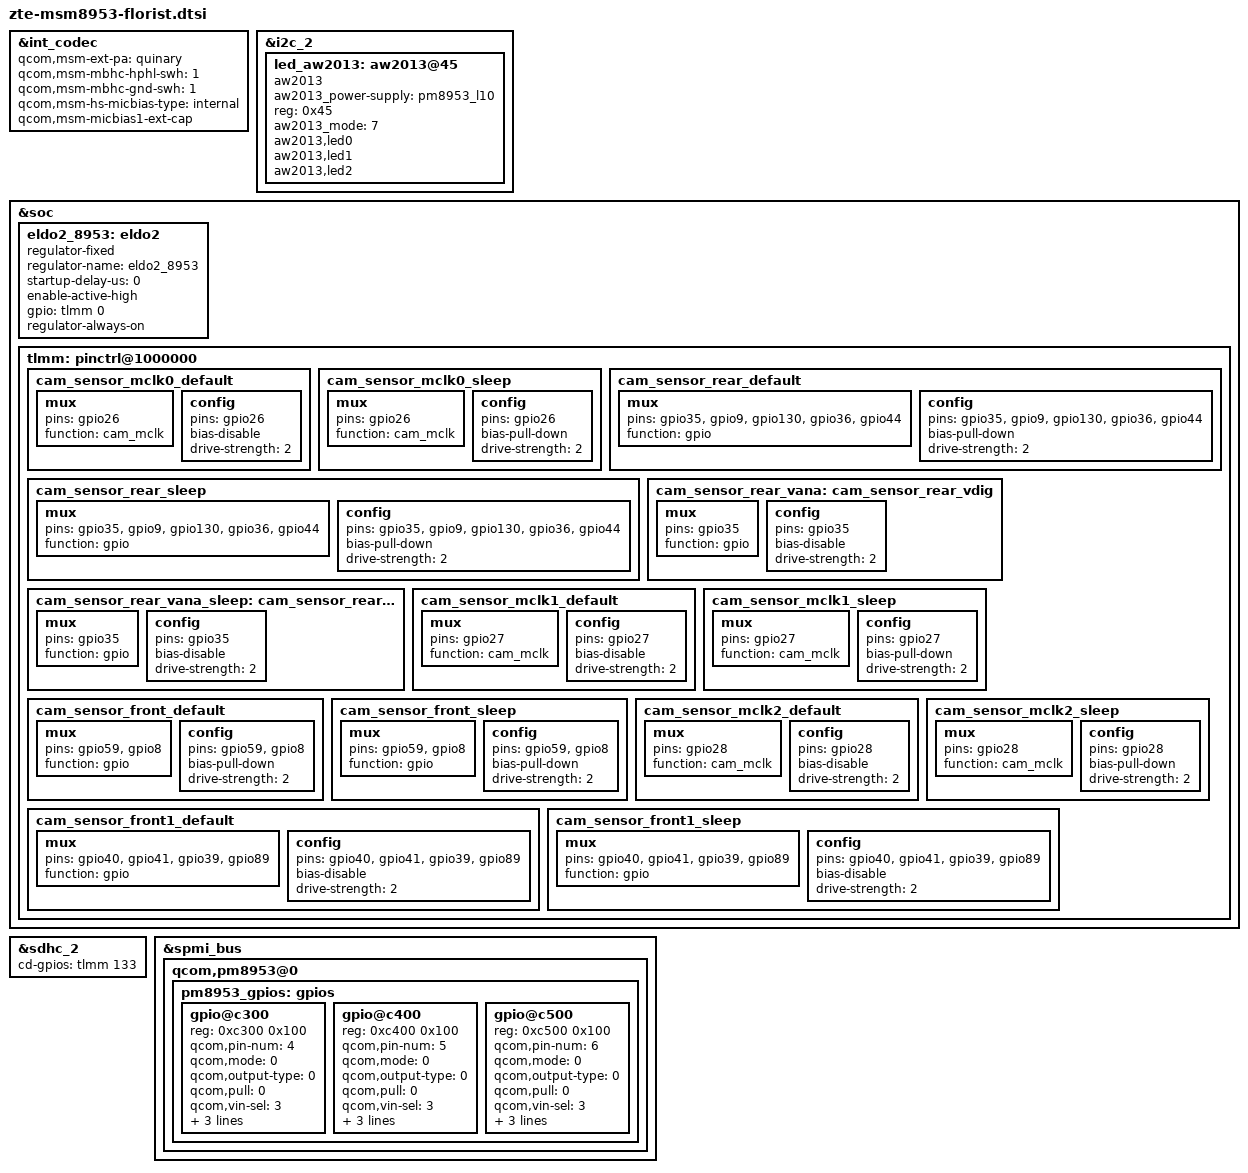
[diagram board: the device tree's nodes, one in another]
/*
 * device tree for zte florist board
 */

#include "touch-key-backlight-florist.dtsi"

&int_codec {
	qcom,msm-ext-pa = "quinary";
	qcom,msm-mbhc-hphl-swh = <1>;
	qcom,msm-mbhc-gnd-swh = <1>;
	qcom,msm-hs-micbias-type = "internal";
	qcom,msm-micbias1-ext-cap;
};

&i2c_2 {
	led_aw2013:aw2013@45 {
		aw2013_power-supply = <&pm8953_l10>;
		compatible = "aw2013";
		reg = <0x45>;
		status = "ok";
		aw2013_mode = < 7 >;
	};
};

&led_aw2013 {
	aw2013,led0;
	aw2013,led1;
	aw2013,led2;
};

&soc {
	eldo2_8953: eldo2 {
		compatible = "regulator-fixed";
		regulator-name = "eldo2_8953";
		startup-delay-us = <0>;
		enable-active-high;
		gpio = <&tlmm 0 0>;
		regulator-always-on;
	};

	tlmm: pinctrl@1000000 {
	/*sensors camera*/
		cam_sensor_mclk0_default: cam_sensor_mclk0_default {
			/* MCLK0 */
			mux {
				/* CLK, DATA */
				pins = "gpio26";
				function = "cam_mclk";
			};

			config {
				pins = "gpio26";
				bias-disable; /* No PULL */
				drive-strength = <2>; /* 2 MA */
			};
		};

		cam_sensor_mclk0_sleep: cam_sensor_mclk0_sleep {
			/* MCLK0 */
			mux {
				/* CLK, DATA */
				pins = "gpio26";
				function = "cam_mclk";
			};

			config {
				pins = "gpio26";
				bias-pull-down; /* PULL DOWN */
				drive-strength = <2>; /* 2 MA */
			};
		};

		cam_sensor_rear_default: cam_sensor_rear_default {
			/* RESET, STANDBY */
			mux {
				pins = "gpio35", "gpio9", "gpio130", "gpio36", "gpio44";
				function = "gpio";
			};

			config {
				pins = "gpio35", "gpio9", "gpio130", "gpio36", "gpio44";
				bias-pull-down; /*pull down*/
				drive-strength = <2>; /* 2 MA */
			};
		};

		cam_sensor_rear_sleep: cam_sensor_rear_sleep {
			/* RESET, STANDBY */
			mux {
				pins = "gpio35", "gpio9", "gpio130", "gpio36", "gpio44";
				function = "gpio";
			};

			config {
				pins = "gpio35", "gpio9", "gpio130", "gpio36", "gpio44";
				bias-pull-down; /*pull down*/
				drive-strength = <2>; /* 2 MA */
			};
		};

		cam_sensor_rear_vana: cam_sensor_rear_vdig {
			/* VDIG */
			mux {
				pins = "gpio35";
				function = "gpio";
			};

			config {
				pins = "gpio35";
				bias-disable; /* No PULL */
				drive-strength = <2>; /* 2 MA */
			};
		};

		cam_sensor_rear_vana_sleep: cam_sensor_rear_vdig_sleep {
			/* VDIG */
			mux {
				pins = "gpio35";
				function = "gpio";
			};

			config {
				pins = "gpio35";
				bias-disable; /* No PULL */
				drive-strength = <2>; /* 2 MA */
			};
		};

		cam_sensor_mclk1_default: cam_sensor_mclk1_default {
			/* MCLK1 */
			mux {
				/* CLK, DATA */
				pins = "gpio27";
				function = "cam_mclk";
			};

			config {
				pins = "gpio27";
				bias-disable; /* No PULL */
				drive-strength = <2>; /* 2 MA */
			};
		};

		cam_sensor_mclk1_sleep: cam_sensor_mclk1_sleep {
			/* MCLK1 */
			mux {
				/* CLK, DATA */
				pins = "gpio27";
				function = "cam_mclk";
			};

			config {
				pins = "gpio27";
				bias-pull-down; /* PULL DOWN */
				drive-strength = <2>; /* 2 MA */
			};
		};

		cam_sensor_front_default: cam_sensor_front_default {
			/* RESET, STANDBY */
			mux {
				pins = "gpio59","gpio8";
				function = "gpio";
			};

			config {
				pins = "gpio59","gpio8";
				bias-pull-down; /* pull down */
				drive-strength = <2>; /* 2 MA */
			};
		};

		cam_sensor_front_sleep: cam_sensor_front_sleep {
			/* RESET, STANDBY */
			mux {
				pins = "gpio59","gpio8";
				function = "gpio";
			};

			config {
				pins = "gpio59","gpio8";
				bias-pull-down; /* pull down */
				drive-strength = <2>; /* 2 MA */
			};
		};

		cam_sensor_mclk2_default: cam_sensor_mclk2_default {
			/* MCLK2 */
			mux {
				/* CLK, DATA */
				pins = "gpio28";
				function = "cam_mclk";
			};

			config {
				pins = "gpio28";
				bias-disable; /* No PULL */
				drive-strength = <2>; /* 2 MA */
			};
		};

		cam_sensor_mclk2_sleep: cam_sensor_mclk2_sleep {
			/* MCLK2 */
			mux {
				/* CLK, DATA */
				pins = "gpio28";
				function = "cam_mclk";
			};

			config {
				pins = "gpio28";
				bias-pull-down; /* PULL DOWN */
				drive-strength = <2>; /* 2 MA */
			};
		};

		cam_sensor_front1_default: cam_sensor_front1_default {
			/* RESET, STANDBY */
			mux {
				pins = "gpio40", "gpio41", "gpio39","gpio89";
				function = "gpio";
			};

			config {
				pins = "gpio40", "gpio41", "gpio39","gpio89";
				bias-disable; /* No PULL */
				drive-strength = <2>; /* 2 MA */
			};
		};

		cam_sensor_front1_sleep: cam_sensor_front1_sleep {
			/* RESET, STANDBY */
			mux {
				pins = "gpio40", "gpio41", "gpio39","gpio89";
				function = "gpio";
			};

			config {
				pins = "gpio40", "gpio41", "gpio39","gpio89";
				bias-disable; /* No PULL */
				drive-strength = <2>; /* 2 MA */
			};
		};
			 };
};
&sdhc_2 {
	cd-gpios = <&tlmm 133 0x0>;
};

&spmi_bus {
	qcom,pm8953@0 {
		pm8953_gpios: gpios {
			gpio@c300 {
				reg = <0xc300 0x100>;
				qcom,pin-num = <4>;
				//status = "disabled";
				qcom,mode = <0>;
				qcom,output-type = <0>;
				qcom,pull = <0>;
				qcom,vin-sel = <3>;
				qcom,out-strength = <3>;
				qcom,src-sel = <0>;
				qcom,master-en = <1>;
				status = "okay";
			};
			gpio@c400 {
				reg = <0xc400 0x100>;
				qcom,pin-num = <5>;
				//status = "disabled";
				qcom,mode = <0>;
				qcom,output-type = <0>;
				qcom,pull = <0>;
				qcom,vin-sel = <3>;
				qcom,out-strength = <3>;
				qcom,src-sel = <0>;
				qcom,master-en = <1>;
				status = "okay";
			};
			gpio@c500 {
				reg = <0xc500 0x100>;
				qcom,pin-num = <6>;
				//status = "disabled";
				qcom,mode = <0>;
				qcom,output-type = <0>;
				qcom,pull = <0>;
				qcom,vin-sel = <3>;
				qcom,out-strength = <3>;
				qcom,src-sel = <0>;
				qcom,master-en = <1>;
				status = "okay";
			};
		};
	};
};
